# STM32F101_iown register map
Vendor: iown-homecontrol; Series: CM3; File version: 1.3
CPU: CM3 r1p1, little endian, no MPU, no FPU, VTOR, 4 interrupt priority bits
Registers are 32-bit, read-write, reset 0x0 unless marked. A register's access mark holds for its fields unless they carry their own. Offsets are from the block's base; [hi:lo] are bit positions; {n}, {i} and the like mark numbered series; 'fields as' and 'values as' point back to an identical list.

## FSMC — Flexible static memory controller
Base 0xA0000000
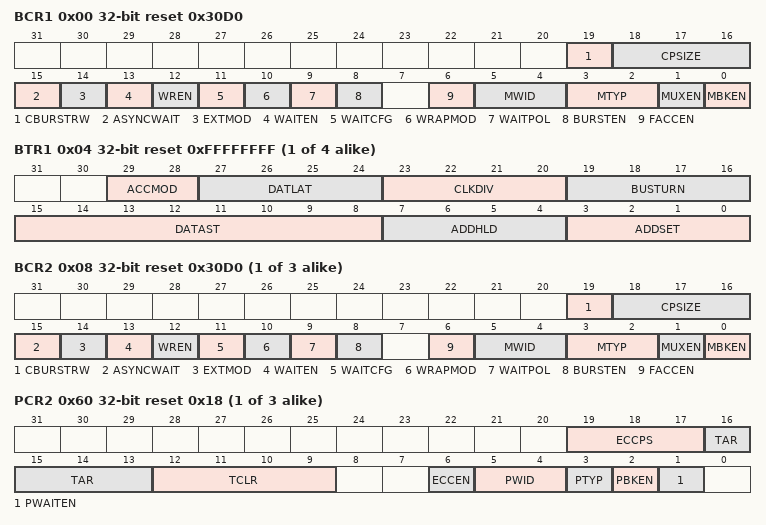
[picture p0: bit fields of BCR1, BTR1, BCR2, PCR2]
0x00 BCR1 reset 0x30D0 — SRAM/NOR-Flash chip-select control register 1
  [19] CBURSTRW
    0=Disabled (Write operations are always performed in asynchronous mode); 1=Enabled (Write operations are performed in synchronous mode)
  [18:16] CPSIZE — CRAM page size
    0=No burst split when crossing page boundary; 1=Bytes128 (128 bytes CRAM page size); 2=Bytes256 (256 bytes CRAM page size); 3=Bytes512 (512 bytes CRAM page size); 4=Bytes1024 (1024 bytes CRAM page size)
  [15] ASYNCWAIT
    0=Disabled (Wait signal not used in asynchronous mode); 1=Enabled (Wait signal used even in asynchronous mode)
  [14] EXTMOD
    0=Disabled (Values inside the FMC_BWTR are not taken into account); 1=Enabled (Values inside the FMC_BWTR are taken into account)
  [13] WAITEN
    0=Disabled (Values inside the FMC_BWTR are taken into account); 1=Enabled (NWAIT signal enabled)
  [12] WREN
    0=Disabled (Write operations disabled for the bank by the FMC); 1=Enabled (Write operations enabled for the bank by the FMC)
  [11] WAITCFG
    0=BeforeWaitState (NWAIT signal is active one data cycle before wait state); 1=DuringWaitState (NWAIT signal is active during wait state)
  [10] WRAPMOD
  [9] WAITPOL
    0=ActiveLow (NWAIT active low); 1=ActiveHigh (NWAIT active high)
  [8] BURSTEN
    0=Disabled (Burst mode disabled); 1=Enabled (Burst mode enabled)
  [6] FACCEN
    0=Disabled (Corresponding NOR Flash memory access is disabled); 1=Enabled (Corresponding NOR Flash memory access is enabled)
  [5:4] MWID
    0=Bits8 (Memory data bus width 8 bits); 1=Bits16 (Memory data bus width 16 bits); 2=Bits32 (Memory data bus width 32 bits)
  [3:2] MTYP
    0=SRAM (SRAM memory type); 1=PSRAM (PSRAM (CRAM) memory type); 2=Flash (NOR Flash/OneNAND Flash)
  [1] MUXEN
    0=Disabled (Address/Data non-multiplexed); 1=Enabled (Address/Data multiplexed on databus)
  [0] MBKEN
    0=Disabled (Corresponding memory bank is disabled); 1=Enabled (Corresponding memory bank is enabled)
0x04 BTR{i} (i=1..4; step 0x8) reset 0xFFFFFFFF — SRAM/NOR-Flash chip-select timing register 1
  [29:28] ACCMOD
    0=A (Access mode A); 1=B (Access mode B); 2=C (Access mode C); 3=D (Access mode D)
  [27:24] DATLAT
  [23:20] CLKDIV range 1..15
  [19:16] BUSTURN
  [15:8] DATAST range 1..255
  [7:4] ADDHLD range 1..15
  [3:0] ADDSET
0x08 BCR{i} (i=2..4; step 0x8) reset 0x30D0 — SRAM/NOR-Flash chip-select control register 2
  fields as BCR1
{0x20+0x20*i} PCR{i} reset 0x18 (i=2..4) — PC Card/NAND Flash control register {i}
  [19:17] ECCPS, [16:13] TAR, [12:9] TCLR, [6] ECCEN, [5:4] PWID, [3] PTYP, [2] PBKEN, [1] PWAITEN
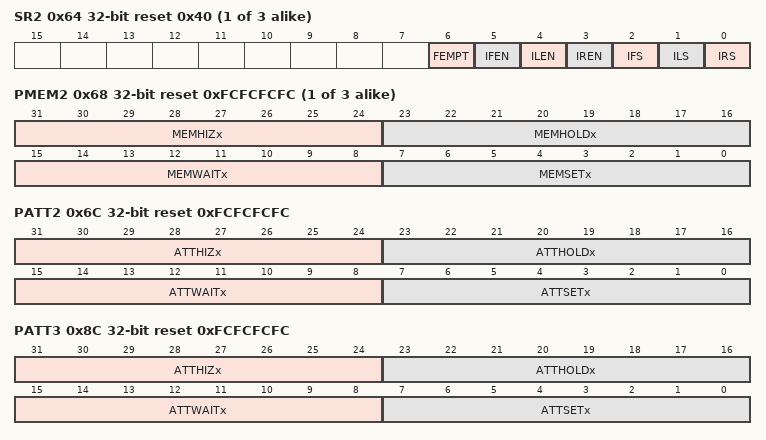
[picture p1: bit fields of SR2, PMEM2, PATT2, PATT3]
{0x24+0x20*i} SR{i} reset 0x40 (i=2..4) — FIFO status and interrupt register {i}
  [6] FEMPT ro, [5] IFEN, [4] ILEN, [3] IREN, [2] IFS, [1] ILS, [0] IRS
{0x28+0x20*i} PMEM{i} reset 0xFCFCFCFC (i=2..4) — Common memory space timing register {i}
  [31:24] MEMHIZx, [23:16] MEMHOLDx, [15:8] MEMWAITx, [7:0] MEMSETx
0x6C PATT2 reset 0xFCFCFCFC — Attribute memory space timing register 2
  [31:24] ATTHIZx — Attribute memory x databus HiZ time
  [23:16] ATTHOLDx — Attribute memory x hold time
  [15:8] ATTWAITx — Attribute memory x wait time
  [7:0] ATTSETx — Attribute memory x setup time
0x74 ECCR2 ro — ECC result register 2
  [31:0] ECCx — ECC result
0x8C PATT3 reset 0xFCFCFCFC — Attribute memory space timing register 3
  [31:24] ATTHIZx, [23:16] ATTHOLDx, [15:8] ATTWAITx, [7:0] ATTSETx
0x94 ECCR3 ro — ECC result register 3
  [31:0] ECCx
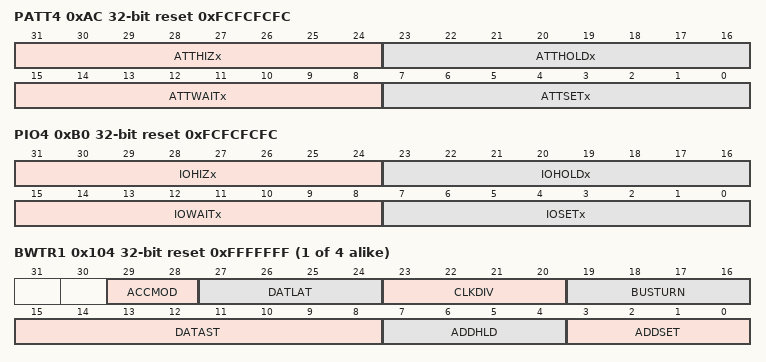
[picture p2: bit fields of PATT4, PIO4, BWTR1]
0xAC PATT4 reset 0xFCFCFCFC — Attribute memory space timing register 4
  [31:24] ATTHIZx, [23:16] ATTHOLDx, [15:8] ATTWAITx, [7:0] ATTSETx
0xB0 PIO4 reset 0xFCFCFCFC — I/O space timing register 4
  [31:24] IOHIZx, [23:16] IOHOLDx, [15:8] IOWAITx, [7:0] IOSETx
{0xFC+8i} BWTR{i} (i=1..4) reset 0xFFFFFFF — SRAM/NOR-Flash write timing registers 1
  [29:28] ACCMOD
    values as BTR{i}.ACCMOD
  [27:24] DATLAT
  [23:20] CLKDIV
  [19:16] BUSTURN — Bus turnaround phase duration
  [15:8] DATAST range 1..255
  [7:4] ADDHLD range 1..15
  [3:0] ADDSET
